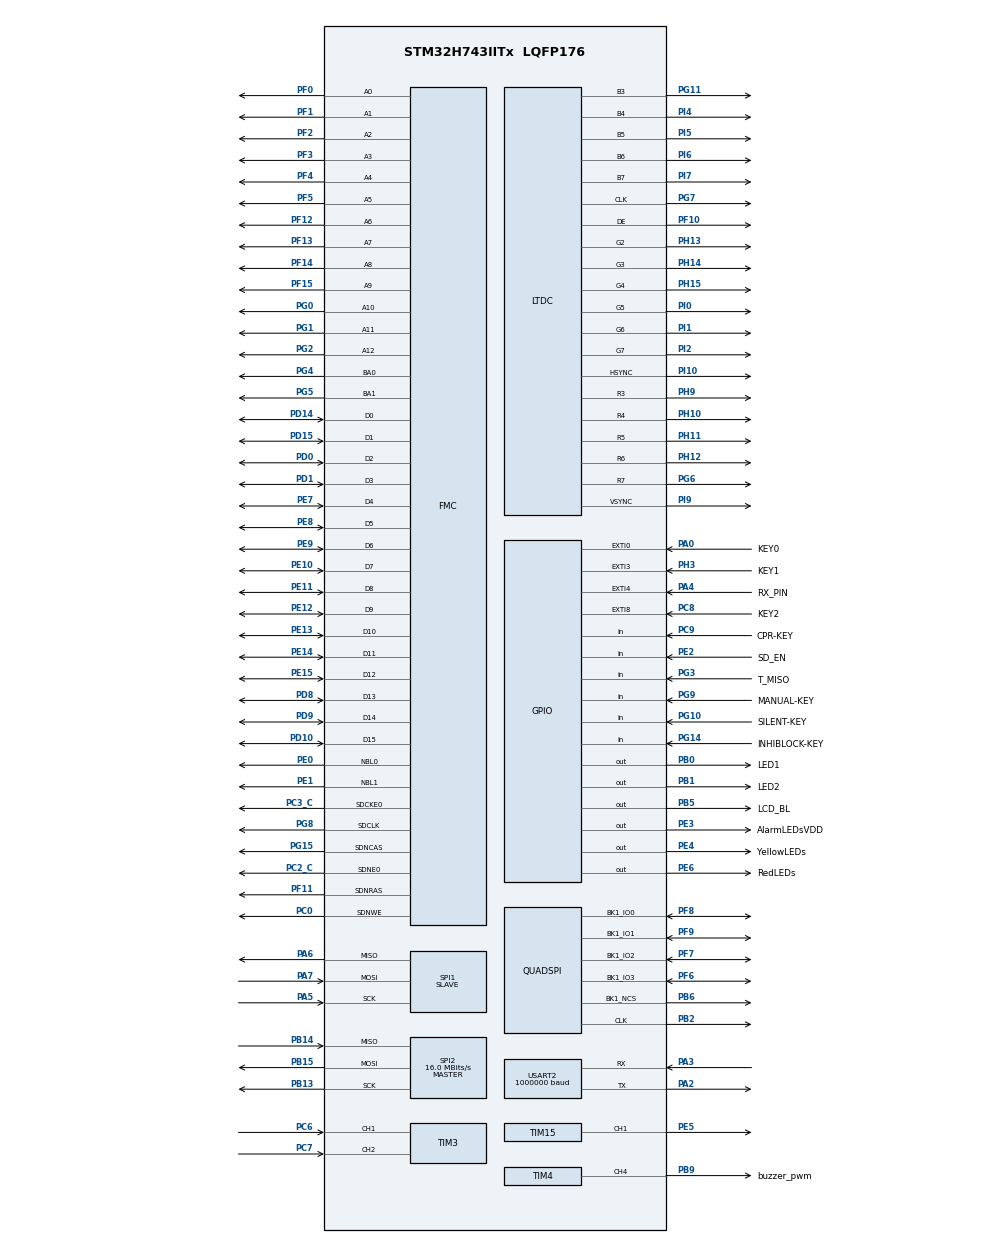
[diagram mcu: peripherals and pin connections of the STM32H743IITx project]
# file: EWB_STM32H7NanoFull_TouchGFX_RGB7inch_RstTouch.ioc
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CORTEX_M7.AccessPermission-Cortex_Memory_Protection_Unit_Region1_Settings=MPU_REGION_FULL_ACCESS
CORTEX_M7.AccessPermission-Cortex_Memory_Protection_Unit_Region2_Settings=MPU_REGION_FULL_ACCESS
CORTEX_M7.AccessPermission-Cortex_Memory_Protection_Unit_Region3_Settings=MPU_REGION_FULL_ACCESS
CORTEX_M7.AccessPermission-Cortex_Memory_Protection_Unit_Region4_Settings=MPU_REGION_FULL_ACCESS
CORTEX_M7.AccessPermission-Cortex_Memory_Protection_Unit_Region5_Settings=MPU_REGION_FULL_ACCESS
CORTEX_M7.AccessPermission-Cortex_Memory_Protection_Unit_Region6_Settings=MPU_REGION_FULL_ACCESS
CORTEX_M7.AccessPermission-Cortex_Memory_Protection_Unit_Region7_Settings=MPU_REGION_FULL_ACCESS
CORTEX_M7.BaseAddress-Cortex_Memory_Protection_Unit_Region1_Settings=0x90000000
CORTEX_M7.BaseAddress-Cortex_Memory_Protection_Unit_Region2_Settings=0xC0000000
CORTEX_M7.BaseAddress-Cortex_Memory_Protection_Unit_Region3_Settings=0x20000000
CORTEX_M7.BaseAddress-Cortex_Memory_Protection_Unit_Region4_Settings=0x24000000
CORTEX_M7.BaseAddress-Cortex_Memory_Protection_Unit_Region5_Settings=0x30000000
CORTEX_M7.BaseAddress-Cortex_Memory_Protection_Unit_Region6_Settings=0x38000000
CORTEX_M7.BaseAddress-Cortex_Memory_Protection_Unit_Region7_Settings=0x60000000
CORTEX_M7.CPU_DCache=Enabled
CORTEX_M7.CPU_ICache=Enabled
CORTEX_M7.DisableExec-Cortex_Memory_Protection_Unit_Region0_Settings=MPU_INSTRUCTION_ACCESS_DISABLE
CORTEX_M7.DisableExec-Cortex_Memory_Protection_Unit_Region2_Settings=MPU_INSTRUCTION_ACCESS_ENABLE
CORTEX_M7.Enable-Cortex_Memory_Protection_Unit_Region0_Settings=MPU_REGION_ENABLE
CORTEX_M7.Enable-Cortex_Memory_Protection_Unit_Region1_Settings=MPU_REGION_ENABLE
CORTEX_M7.Enable-Cortex_Memory_Protection_Unit_Region2_Settings=MPU_REGION_ENABLE
CORTEX_M7.Enable-Cortex_Memory_Protection_Unit_Region3_Settings=MPU_REGION_ENABLE
CORTEX_M7.Enable-Cortex_Memory_Protection_Unit_Region4_Settings=MPU_REGION_ENABLE
CORTEX_M7.Enable-Cortex_Memory_Protection_Unit_Region5_Settings=MPU_REGION_ENABLE
CORTEX_M7.Enable-Cortex_Memory_Protection_Unit_Region6_Settings=MPU_REGION_ENABLE
CORTEX_M7.Enable-Cortex_Memory_Protection_Unit_Region7_Settings=MPU_REGION_ENABLE
CORTEX_M7.Enable-Cortex_Memory_Protection_Unit_Region8_Settings=__NULL
CORTEX_M7.IsBufferable-Cortex_Memory_Protection_Unit_Region2_Settings=MPU_ACCESS_BUFFERABLE
CORTEX_M7.IsBufferable-Cortex_Memory_Protection_Unit_Region3_Settings=MPU_ACCESS_BUFFERABLE
CORTEX_M7.IsBufferable-Cortex_Memory_Protection_Unit_Region4_Settings=MPU_ACCESS_BUFFERABLE
CORTEX_M7.IsBufferable-Cortex_Memory_Protection_Unit_Region5_Settings=MPU_ACCESS_BUFFERABLE
CORTEX_M7.IsBufferable-Cortex_Memory_Protection_Unit_Region6_Settings=MPU_ACCESS_BUFFERABLE
CORTEX_M7.IsCacheable-Cortex_Memory_Protection_Unit_Region1_Settings=MPU_ACCESS_CACHEABLE
CORTEX_M7.IsCacheable-Cortex_Memory_Protection_Unit_Region2_Settings=MPU_ACCESS_CACHEABLE
CORTEX_M7.IsCacheable-Cortex_Memory_Protection_Unit_Region3_Settings=MPU_ACCESS_CACHEABLE
CORTEX_M7.IsCacheable-Cortex_Memory_Protection_Unit_Region4_Settings=MPU_ACCESS_CACHEABLE
CORTEX_M7.IsCacheable-Cortex_Memory_Protection_Unit_Region5_Settings=MPU_ACCESS_CACHEABLE
CORTEX_M7.IsCacheable-Cortex_Memory_Protection_Unit_Region6_Settings=MPU_ACCESS_CACHEABLE
CORTEX_M7.IsShareable-Cortex_Memory_Protection_Unit_Region0_Settings=MPU_ACCESS_SHAREABLE
CORTEX_M7.MPU_Control=__NULL
CORTEX_M7.Size-Cortex_Memory_Protection_Unit_Region0_Settings=MPU_REGION_SIZE_4GB
CORTEX_M7.Size-Cortex_Memory_Protection_Unit_Region1_Settings=MPU_REGION_SIZE_32MB
CORTEX_M7.Size-Cortex_Memory_Protection_Unit_Region2_Settings=MPU_REGION_SIZE_32MB
CORTEX_M7.Size-Cortex_Memory_Protection_Unit_Region3_Settings=MPU_REGION_SIZE_128KB
CORTEX_M7.Size-Cortex_Memory_Protection_Unit_Region4_Settings=MPU_REGION_SIZE_512KB
CORTEX_M7.Size-Cortex_Memory_Protection_Unit_Region5_Settings=MPU_REGION_SIZE_512KB
CORTEX_M7.Size-Cortex_Memory_Protection_Unit_Region6_Settings=MPU_REGION_SIZE_64KB
CORTEX_M7.Size-Cortex_Memory_Protection_Unit_Region7_Settings=MPU_REGION_SIZE_64KB
CORTEX_M7.SubRegionDisable-Cortex_Memory_Protection_Unit_Region0_Settings=0x87
DMA2D.ColorMode=DMA2D_OUTPUT_RGB565
FMC.CASLatency1=FMC_SDRAM_CAS_LATENCY_3
FMC.ColumnBitsNumber1=FMC_SDRAM_COLUMN_BITS_NUM_9
FMC.ExitSelfRefreshDelay1=8
FMC.LoadToActiveDelay1=2
FMC.RCDDelay1=2
FMC.RPDelay1=2
FMC.RPDelay2=2
FMC.ReadBurst1=FMC_SDRAM_RBURST_ENABLE
FMC.ReadBurst2=FMC_SDRAM_RBURST_ENABLE
FMC.ReadPipeDelay1=FMC_SDRAM_RPIPE_DELAY_0
FMC.RowCycleDelay1=7
FMC.RowCycleDelay2=7
FMC.SDClockPeriod1=FMC_SDRAM_CLOCK_PERIOD_2
FMC.SDClockPeriod2=FMC_SDRAM_CLOCK_PERIOD_2
FMC.SelfRefreshTime1=5
FMC.WriteRecoveryTime1=4
LTDC.ActiveH=600
LTDC.ActiveW=800
LTDC.Alpha_L0=255
LTDC.Alpha_L1=255
LTDC.FBStartAdress_L0=0xC0000000
LTDC.Green_L0=0
LTDC.HBP=46
LTDC.HFP=210
LTDC.HSync=1
LTDC.ImageHeight_L0=600
LTDC.ImageHeight_L1=480
LTDC.ImageWidth_L0=800
LTDC.Layers=0
LTDC.PixelFormat_L0=LTDC_PIXEL_FORMAT_RGB565
LTDC.Red_L0=0
LTDC.VBP=23
LTDC.VFP=12
LTDC.VSync=13
LTDC.WindowX0_L0=0
LTDC.WindowX1_L0=800
LTDC.WindowX1_L1=800
LTDC.WindowY0_L0=0
LTDC.WindowY1_L0=600
LTDC.WindowY1_L1=480
Mcu.Family=STM32H7
Mcu.Name=STM32H743IITx
Mcu.Package=LQFP176
NVIC.DMA2D_IRQn=true\:0\:0\:false\:false\:true\:true\:true\:true
NVIC.EXTI0_IRQn=true\:0\:0\:false\:false\:true\:true\:true\:true
NVIC.EXTI3_IRQn=true\:0\:0\:false\:false\:true\:true\:true\:true
NVIC.EXTI4_IRQn=true\:0\:0\:false\:false\:true\:true\:true\:true
NVIC.EXTI9_5_IRQn=true\:0\:0\:false\:false\:true\:true\:true\:true
NVIC.LTDC_ER_IRQn=true\:0\:0\:false\:false\:true\:true\:true\:true
NVIC.LTDC_IRQn=true\:0\:0\:false\:false\:true\:true\:true\:true
NVIC.PriorityGroup=NVIC_PRIORITYGROUP_4
NVIC.SPI1_IRQn=true\:0\:0\:false\:false\:true\:true\:true\:true
NVIC.TIM2_IRQn=true\:0\:0\:false\:false\:true\:true\:true\:true
NVIC.TIM3_IRQn=true\:0\:0\:false\:false\:true\:true\:true\:true
NVIC.TIM6_DAC_IRQn=true\:15\:0\:false\:false\:true\:false\:true\:true
NVIC.TimeBase=TIM6_DAC_IRQn
NVIC.TimeBaseIP=TIM6
PA0.GPIO_Label=KEY0
PA0.GPIO_ModeDefaultEXTI=GPIO_MODE_IT_RISING
PA0.GPIO_PuPd=GPIO_NOPULL
PA0.Signal=GPXTI0
PA13\ (JTMS/SWDIO).Mode=Serial_Wire
PA13\ (JTMS/SWDIO).Signal=DEBUG_JTMS-SWDIO
PA14\ (JTCK/SWCLK).Mode=Serial_Wire
PA14\ (JTCK/SWCLK).Signal=DEBUG_JTCK-SWCLK
PA2.Mode=Asynchronous
PA2.Signal=USART2_TX
PA3.Mode=Asynchronous
PA3.Signal=USART2_RX
PA4.GPIO_Label=RX_PIN
PA4.Signal=GPXTI4
PA5.Mode=Full_Duplex_Slave
PA5.Signal=SPI1_SCK
PA6.Mode=Full_Duplex_Slave
PA6.Signal=SPI1_MISO
PA7.Mode=Full_Duplex_Slave
PA7.Signal=SPI1_MOSI
PB0.GPIO_Label=LED1
PB0.GPIO_Speed=GPIO_SPEED_FREQ_VERY_HIGH
PB0.PinState=GPIO_PIN_RESET
PB0.Signal=GPIO_Output
PB1.GPIO_Label=LED2
PB1.GPIO_Speed=GPIO_SPEED_FREQ_VERY_HIGH
PB1.Signal=GPIO_Output
PB13.Mode=Full_Duplex_Master
PB13.Signal=SPI2_SCK
PB14.Mode=Full_Duplex_Master
PB14.Signal=SPI2_MISO
PB15.Mode=Full_Duplex_Master
PB15.Signal=SPI2_MOSI
PB2.GPIO_Speed=GPIO_SPEED_FREQ_VERY_HIGH
PB2.Mode=Single Bank 1
PB2.Signal=QUADSPI_CLK
PB5.GPIO_Label=LCD_BL
PB5.GPIO_Speed=GPIO_SPEED_FREQ_VERY_HIGH
PB5.PinState=GPIO_PIN_RESET
PB5.Signal=GPIO_Output
PB6.GPIO_FM6=SYSCFG_PMCR_I2C_PB6_FMP
PB6.GPIO_Speed=GPIO_SPEED_FREQ_VERY_HIGH
PB6.Mode=Single Bank 1
PB6.Signal=QUADSPI_BK1_NCS
PB9.GPIO_Label=buzzer_pwm
PB9.Signal=S_TIM4_CH4
PC0.Signal=FMC_SDNWE
PC14-OSC32_IN\ (OSC32_IN).Mode=LSE-External-Oscillator
PC14-OSC32_IN\ (OSC32_IN).Signal=RCC_OSC32_IN
PC15-OSC32_OUT\ (OSC32_OUT).Mode=LSE-External-Oscillator
PC15-OSC32_OUT\ (OSC32_OUT).Signal=RCC_OSC32_OUT
PC2_C.Mode=SdramChipSelect1_1
PC2_C.Signal=FMC_SDNE0
PC3_C.Mode=SdramChipSelect1_1
PC3_C.Signal=FMC_SDCKE0
PC6.GPIO_PuPd=GPIO_PULLUP
PC6.GPIO_Speed=GPIO_SPEED_FREQ_LOW
PC6.Signal=S_TIM3_CH1
PC7.GPIO_PuPd=GPIO_PULLUP
PC7.GPIO_Speed=GPIO_SPEED_FREQ_LOW
PC7.Signal=S_TIM3_CH2
PC8.GPIO_Label=KEY2
PC8.Signal=GPXTI8
PC9.GPIO_Label=CPR-KEY
PC9.GPIO_PuPd=GPIO_PULLUP
PC9.Signal=GPIO_Input
PD0.Signal=FMC_D2_DA2
PD1.Signal=FMC_D3_DA3
PD10.Signal=FMC_D15_DA15
PD14.Signal=FMC_D0_DA0
PD15.Signal=FMC_D1_DA1
PD8.Signal=FMC_D13_DA13
PD9.Signal=FMC_D14_DA14
PE0.Signal=FMC_NBL0
PE1.Signal=FMC_NBL1
PE10.Signal=FMC_D7_DA7
PE11.Signal=FMC_D8_DA8
PE12.Signal=FMC_D9_DA9
PE13.Signal=FMC_D10_DA10
PE14.Signal=FMC_D11_DA11
PE15.Signal=FMC_D12_DA12
PE2.GPIO_Label=SD_EN
PE2.GPIO_PuPd=GPIO_PULLDOWN
PE2.Signal=GPIO_Input
PE3.GPIO_Label=AlarmLEDsVDD
PE3.Signal=GPIO_Output
PE4.GPIO_Label=YellowLEDs
PE4.GPIO_PuPd=GPIO_PULLDOWN
PE4.Signal=GPIO_Output
PE5.Signal=S_TIM15_CH1
PE6.GPIO_Label=RedLEDs
PE6.GPIO_PuPd=GPIO_PULLDOWN
PE6.Signal=GPIO_Output
PE7.Signal=FMC_D4_DA4
PE8.Signal=FMC_D5_DA5
PE9.Signal=FMC_D6_DA6
PF0.Signal=FMC_A0
PF1.Signal=FMC_A1
PF10.GPIO_Speed=GPIO_SPEED_FREQ_VERY_HIGH
PF10.Mode=RGB565
PF10.Signal=LTDC_DE
PF11.Signal=FMC_SDNRAS
PF12.Signal=FMC_A6
PF13.Signal=FMC_A7
PF14.Signal=FMC_A8
PF15.Signal=FMC_A9
PF2.Signal=FMC_A2
PF3.Signal=FMC_A3
PF4.Signal=FMC_A4
PF5.Signal=FMC_A5
PF6.GPIO_Speed=GPIO_SPEED_FREQ_VERY_HIGH
PF6.Mode=Single Bank 1
PF6.Signal=QUADSPI_BK1_IO3
PF7.GPIO_Speed=GPIO_SPEED_FREQ_VERY_HIGH
PF7.Mode=Single Bank 1
PF7.Signal=QUADSPI_BK1_IO2
PF8.GPIO_Speed=GPIO_SPEED_FREQ_VERY_HIGH
PF8.Mode=Single Bank 1
PF8.Signal=QUADSPI_BK1_IO0
PF9.GPIO_Speed=GPIO_SPEED_FREQ_VERY_HIGH
PF9.Mode=Single Bank 1
PF9.Signal=QUADSPI_BK1_IO1
PG0.Signal=FMC_A10
PG1.Signal=FMC_A11
PG10.GPIO_Label=SILENT-KEY
PG10.GPIO_PuPd=GPIO_PULLUP
PG10.Signal=GPIO_Input
PG11.GPIO_Speed=GPIO_SPEED_FREQ_VERY_HIGH
PG11.Mode=RGB565
PG11.Signal=LTDC_B3
PG14.GPIO_Label=INHIBLOCK-KEY
PG14.GPIO_PuPd=GPIO_PULLUP
PG14.Signal=GPIO_Input
PG15.Signal=FMC_SDNCAS
PG2.Signal=FMC_A12
PG3.GPIO_Label=T_MISO
PG3.Signal=GPIO_Input
PG4.Signal=FMC_A14_BA0
PG5.Signal=FMC_A15_BA1
PG6.GPIO_Speed=GPIO_SPEED_FREQ_VERY_HIGH
PG6.Mode=RGB565
PG6.Signal=LTDC_R7
PG7.GPIO_Speed=GPIO_SPEED_FREQ_VERY_HIGH
PG7.Mode=RGB565
PG7.Signal=LTDC_CLK
PG8.Signal=FMC_SDCLK
PG9.GPIO_Label=MANUAL-KEY
PG9.GPIO_PuPd=GPIO_PULLUP
PG9.Signal=GPIO_Input
PH0-OSC_IN\ (PH0).Mode=HSE-External-Oscillator
PH0-OSC_IN\ (PH0).Signal=RCC_OSC_IN
PH1-OSC_OUT\ (PH1).Mode=HSE-External-Oscillator
PH1-OSC_OUT\ (PH1).Signal=RCC_OSC_OUT
PH10.GPIO_Speed=GPIO_SPEED_FREQ_VERY_HIGH
PH10.Mode=RGB565
PH10.Signal=LTDC_R4
PH11.GPIO_Speed=GPIO_SPEED_FREQ_VERY_HIGH
PH11.Mode=RGB565
PH11.Signal=LTDC_R5
PH12.GPIO_Speed=GPIO_SPEED_FREQ_VERY_HIGH
PH12.Mode=RGB565
PH12.Signal=LTDC_R6
PH13.GPIO_Speed=GPIO_SPEED_FREQ_VERY_HIGH
PH13.Mode=RGB565
PH13.Signal=LTDC_G2
PH14.GPIO_Speed=GPIO_SPEED_FREQ_VERY_HIGH
PH14.Mode=RGB565
PH14.Signal=LTDC_G3
PH15.GPIO_Speed=GPIO_SPEED_FREQ_VERY_HIGH
PH15.Mode=RGB565
PH15.Signal=LTDC_G4
PH3.GPIO_Label=KEY1
PH3.Signal=GPXTI3
PH4.GPIO_Pu=GPIO_PULLUP
PH4.GPIO_Speed=GPIO_SPEED_FREQ_VERY_HIGH
PH4.Signal=I2C2_SCL
PH5.GPIO_Pu=GPIO_PULLUP
PH5.GPIO_Speed=GPIO_SPEED_FREQ_VERY_HIGH
PH5.Signal=I2C2_SDA
PH9.GPIO_Speed=GPIO_SPEED_FREQ_VERY_HIGH
PH9.Mode=RGB565
PH9.Signal=LTDC_R3
PI0.GPIO_Speed=GPIO_SPEED_FREQ_VERY_HIGH
PI0.Mode=RGB565
PI0.Signal=LTDC_G5
PI1.GPIO_Speed=GPIO_SPEED_FREQ_VERY_HIGH
PI1.Mode=RGB565
PI1.Signal=LTDC_G6
PI10.GPIO_Speed=GPIO_SPEED_FREQ_VERY_HIGH
PI10.Mode=RGB565
PI10.Signal=LTDC_HSYNC
PI2.GPIO_Speed=GPIO_SPEED_FREQ_VERY_HIGH
PI2.Mode=RGB565
PI2.Signal=LTDC_G7
PI4.GPIO_Speed=GPIO_SPEED_FREQ_VERY_HIGH
PI4.Mode=RGB565
PI4.Signal=LTDC_B4
PI5.GPIO_Speed=GPIO_SPEED_FREQ_VERY_HIGH
PI5.Mode=RGB565
PI5.Signal=LTDC_B5
PI6.GPIO_Speed=GPIO_SPEED_FREQ_VERY_HIGH
PI6.Mode=RGB565
PI6.Signal=LTDC_B6
PI7.GPIO_Speed=GPIO_SPEED_FREQ_VERY_HIGH
PI7.Mode=RGB565
PI7.Signal=LTDC_B7
PI9.GPIO_Speed=GPIO_SPEED_FREQ_VERY_HIGH
PI9.Mode=RGB565
PI9.Signal=LTDC_VSYNC
ProjectManager.HeapSize=0x2000
ProjectManager.StackSize=0x2000
ProjectManager.TargetToolchain=MDK-ARM V5.32
QUADSPI.ChipSelectHighTime=QSPI_CS_HIGH_TIME_1_CYCLE
QUADSPI.ClockMode=QSPI_CLOCK_MODE_3
QUADSPI.ClockPrescaler=4
QUADSPI.FifoThreshold=4
QUADSPI.FlashSize=24
QUADSPI.SampleShifting=QSPI_SAMPLE_SHIFTING_HALFCYCLE
RCC.ADCFreq_Value=133000000
RCC.APB1Freq_Value=100000000
RCC.APB2Freq_Value=100000000
RCC.APB3Freq_Value=100000000
RCC.APB4Freq_Value=100000000
RCC.CortexFreq_Value=400000000
RCC.D1PPRE=RCC_APB3_DIV2
RCC.D2PPRE1=RCC_APB1_DIV2
RCC.D2PPRE2=RCC_APB2_DIV2
RCC.D3PPRE=RCC_APB4_DIV2
RCC.DIVM1=5
RCC.DIVM2=25
RCC.DIVM3=25
RCC.DIVN1=160
RCC.DIVN2=266
RCC.DIVN3=330
RCC.DIVQ1=8
RCC.DIVR1=4
RCC.DIVR3=10
RCC.FMCCLockSelection=RCC_FMCCLKSOURCE_PLL2
RCC.HCLKFreq_Value=200000000
RCC.HPRE=RCC_HCLK_DIV2
RCC.LSE_Drive_Capability=RCC_LSEDRIVE_MEDIUMHIGH
RCC.PLL2FRACN=0
RCC.PLL3FRACN=0
RCC.PLLFRACN=0
RCC.PLLSourceVirtual=RCC_PLLSOURCE_HSE
RCC.QSPICLockSelection=RCC_QSPICLKSOURCE_PLL
RCC.RTCClockSelection=RCC_RTCCLKSOURCE_LSE
RCC.SPI123CLockSelection=RCC_SPI123CLKSOURCE_CLKP
RCC.SYSCLKFreq_VALUE=400000000
RCC.SYSCLKSource=RCC_SYSCLKSOURCE_PLLCLK
RCC.USBFreq_Value=100000000
RTC.Date=7
RTC.Format=RTC_FORMAT_BIN
RTC.Hours=18
RTC.Minutes=20
RTC.Month=RTC_MONTH_NOVEMBER
RTC.Seconds=30
RTC.WeekDay=RTC_WEEKDAY_TUESDAY
RTC.Year=23
SH.FMC_A0.0=FMC_A0,13b-sda1
SH.FMC_A1.0=FMC_A1,13b-sda1
SH.FMC_A10.0=FMC_A10,13b-sda1
SH.FMC_A11.0=FMC_A11,13b-sda1
SH.FMC_A12.0=FMC_A12,13b-sda1
SH.FMC_A14_BA0.0=FMC_BA0,FourSdramBanks1
SH.FMC_A15_BA1.0=FMC_BA1,FourSdramBanks1
SH.FMC_A2.0=FMC_A2,13b-sda1
SH.FMC_A3.0=FMC_A3,13b-sda1
SH.FMC_A4.0=FMC_A4,13b-sda1
SH.FMC_A5.0=FMC_A5,13b-sda1
SH.FMC_A6.0=FMC_A6,13b-sda1
SH.FMC_A7.0=FMC_A7,13b-sda1
SH.FMC_A8.0=FMC_A8,13b-sda1
SH.FMC_A9.0=FMC_A9,13b-sda1
SH.FMC_D0_DA0.0=FMC_D0,sd-16b-d1
SH.FMC_D10_DA10.0=FMC_D10,sd-16b-d1
SH.FMC_D11_DA11.0=FMC_D11,sd-16b-d1
SH.FMC_D12_DA12.0=FMC_D12,sd-16b-d1
SH.FMC_D13_DA13.0=FMC_D13,sd-16b-d1
SH.FMC_D14_DA14.0=FMC_D14,sd-16b-d1
SH.FMC_D15_DA15.0=FMC_D15,sd-16b-d1
SH.FMC_D1_DA1.0=FMC_D1,sd-16b-d1
SH.FMC_D2_DA2.0=FMC_D2,sd-16b-d1
SH.FMC_D3_DA3.0=FMC_D3,sd-16b-d1
SH.FMC_D4_DA4.0=FMC_D4,sd-16b-d1
SH.FMC_D5_DA5.0=FMC_D5,sd-16b-d1
SH.FMC_D6_DA6.0=FMC_D6,sd-16b-d1
SH.FMC_D7_DA7.0=FMC_D7,sd-16b-d1
SH.FMC_D8_DA8.0=FMC_D8,sd-16b-d1
SH.FMC_D9_DA9.0=FMC_D9,sd-16b-d1
SH.FMC_NBL0.0=FMC_NBL0,Sd2ByteEnable1
SH.FMC_NBL1.0=FMC_NBL1,Sd2ByteEnable1
SH.FMC_SDCLK.0=FMC_SDCLK,13b-sda1
SH.FMC_SDNCAS.0=FMC_SDNCAS,13b-sda1
SH.FMC_SDNRAS.0=FMC_SDNRAS,13b-sda1
SH.FMC_SDNWE.0=FMC_SDNWE,13b-sda1
SH.S_TIM15_CH1.0=TIM15_CH1,PWM Generation1 CH1
SH.S_TIM3_CH1.0=TIM3_CH1,Encoder_Interface
SH.S_TIM3_CH2.0=TIM3_CH2,Encoder_Interface
SH.S_TIM4_CH4.0=TIM4_CH4,PWM Generation4 CH4
SPI1.DataSize=SPI_DATASIZE_8BIT
SPI1.Direction=SPI_DIRECTION_2LINES
SPI1.Mode=SPI_MODE_SLAVE
SPI1.VirtualType=VM_SLAVE
SPI2.BaudRatePrescaler=SPI_BAUDRATEPRESCALER_4
SPI2.CalculateBaudRate=16.0 MBits/s
SPI2.DataSize=SPI_DATASIZE_8BIT
SPI2.Direction=SPI_DIRECTION_2LINES
SPI2.Mode=SPI_MODE_MASTER
SPI2.VirtualType=VM_MASTER
STMicroelectronics.X-CUBE-TOUCHGFX.4.20.0.ApplicationCcGraphicsJjApplication=TouchGFXOoGenerator
STMicroelectronics.X-CUBE-TOUCHGFX.4.20.0.tgfx_address1=0xC0000000
STMicroelectronics.X-CUBE-TOUCHGFX.4.20.0.tgfx_address2=0xC00EA600
STMicroelectronics.X-CUBE-TOUCHGFX.4.20.0.tgfx_buffering_strategy=Double
STMicroelectronics.X-CUBE-TOUCHGFX.4.20.0.tgfx_display_interface=disp_ltdc
STMicroelectronics.X-CUBE-TOUCHGFX.4.20.0.tgfx_hardware_accelerator=dma_2d
STMicroelectronics.X-CUBE-TOUCHGFX.4.20.0.tgfx_location=By Address
STMicroelectronics.X-CUBE-TOUCHGFX.4.20.0.tgfx_video=Disabled
STMicroelectronics.X-CUBE-TOUCHGFX.4.20.0.tgfx_video_buffer_format=RGB565\:2
STMicroelectronics.X-CUBE-TOUCHGFX.4.20.0.tgfx_video_height=272
STMicroelectronics.X-CUBE-TOUCHGFX.4.20.0.tgfx_video_strategy=2
STMicroelectronics.X-CUBE-TOUCHGFX.4.20.0.tgfx_video_streams=1
STMicroelectronics.X-CUBE-TOUCHGFX.4.20.0.tgfx_video_width=480
STMicroelectronics.X-CUBE-TOUCHGFX.4.20.0.tgfx_vsync=vsync_ltdc
STMicroelectronics.X-CUBE-TOUCHGFX.4.20.0_IsPackSelfContextualization=true
TIM15.Channel-PWM\ Generation1\ CH1=TIM_CHANNEL_1
TIM15.Period=99
TIM15.Prescaler=1999
TIM2.Period=9999
TIM2.Prescaler=999
TIM3.EncoderMode=TIM_ENCODERMODE_TI12
TIM3.IC1Filter=10
TIM3.IC1Polarity=TIM_ICPOLARITY_FALLING
TIM3.IC2Filter=10
TIM3.IC2Polarity=TIM_ICPOLARITY_FALLING
TIM4.Channel-PWM\ Generation4\ CH4=TIM_CHANNEL_4
TIM4.Period=99
TIM4.Prescaler=2500
USART2.BaudRate=1000000
USART2.VirtualMode-Asynchronous=VM_ASYNC
VP_CRC_VS_CRC.Mode=CRC_Activate
VP_DMA2D_VS_DMA2D.Mode=DMA2D_Activate
VP_RTC_VS_RTC_Activate.Mode=RTC_Enabled
VP_RTC_VS_RTC_Calendar.Mode=RTC_Calendar
VP_STMicroelectronics.X-CUBE-TOUCHGFX_VS_GraphicsJjApplication_4.20.0.Mode=GraphicsJjApplication
VP_SYS_VS_tim6.Mode=TIM6
VP_TIM15_VS_ClockSourceINT.Mode=Internal
VP_TIM2_VS_ClockSourceINT.Mode=Internal
VP_TIM4_VS_ClockSourceINT.Mode=Internal
board=custom

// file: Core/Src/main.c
/* USER CODE BEGIN Header */
/**
  ******************************************************************************
  * @file           : main.c
  * @brief          : Main program body
  ******************************************************************************
  * @attention
  *
  * <h2><center>&copy; Copyright (c) 2022 STMicroelectronics.
  * All rights reserved.</center></h2>
  *
  * This software component is licensed by ST under Ultimate Liberty license
  * SLA0044, the "License"; You may not use this file except in compliance with
  * the License. You may obtain a copy of the License at:
  *                             www.st.com/SLA0044
  *
  ******************************************************************************
  */
/* USER CODE END Header */
#include "main.h"
#include "crc.h"
#include "dma2d.h"
#include "ltdc.h"
#include "quadspi.h"
#include "rtc.h"
#include "spi.h"
#include "tim.h"
#include "usart.h"
#include "gpio.h"
#include "fmc.h"
#include "app_touchgfx.h"

/* USER CODE BEGIN Includes */
#include <string.h>
#include "dwt_stm32_delay.h"
#include "touch_800x480.h"
#include "stdlib.h"
#include "stdio.h"
#include "Buzzer.h"
/* USER CODE END Includes */

/* USER CODE BEGIN PD */
#define BUFFER_SIZE 700

/* USER CODE END PD */

/* USER CODE BEGIN PV */
int vdd = 0;
int yel = 0;
int red = 0;

uint8_t tx_data[700] = "data";
int config_ok = 1; //yes = 1 / no = 0
int state_IE = 0;  //I = 0 / E = 1
int state_I_begin = 0; //begin I = 0
int state_E_begin = 0; //begin E = 0
int counter_timer_I = 0; //time inspritory
int counter_timer_E = 0; //time expirtory
int Counter_timer_T = 0;
int my_t = 0; //for recording
int my_value = 0;
int taghsim = 0;

uint8_t isAlerting = 0; // 0:false, 1:true
float flag_startVent = 0;
float lockScreen_intval = 0; // 0:off, 1:on
float CPR_intval = 0; // 0:off, 1:on
int isLockChanged = 0;
int isCPRChanged = 0;
float manualBreath_intval = 0;
float silent_intval = 0;

float Voltage = 0;
uint16_t VoltageByte;

float RR_real;
float Ti_real;
float TiInspPause_real;
float Te_real;
float VT_real;
float VTi_real;
float VTe_real;
float flow_real;
float FiO2_real=21;
float SPO2_real;
float LeakExp_real;
float pressure_real;
float pip_real;
float peep_real;
float PIF_real;
float IPP_real;
float CMPL_real;
float AVP_real;
float Patm_real;
float leak_real;
float MVe_real;
float MVi_real;
float Res_real;
float alarm_real[6];
float bat_real;
float PEF_real;
float RSBI_real;
float SpontTrig_real;
float SpontCycle_real;
float circuitDis_real;
float pulseRate_real;
float obstruction_real;
float check_data;
float measureBattTime_real;
float externalDC_real;
float tightness_result;
float flowSensor_forward_result;
float flowSensor_backward_result;
float calib_process;

float old_check_data = 0;
float fault_recieve = 0; // 0 no fault // 1 fault in recieve

RTC_TimeTypeDef RTC_Time;
RTC_DateTypeDef RTC_Date;

uint32_t flag = 0;
uint32_t record=0;

uint16_t x,y;
int resetIT=0;

uint8_t data[4]="data";

uint8_t rx_buffer[BUFFER_SIZE] = {0};
//uint8_t tx_buffer[BUFFER_SIZE] = {0};
int counter=0;
/* USER CODE END PV */

void SystemClock_Config(void);
void PeriphCommonClock_Config(void);

/* USER CODE BEGIN 0 */
void HAL_SPI_RxCpltCallback(SPI_HandleTypeDef *hspi)
{
	counter++;
	HAL_SPI_Receive_IT(&hspi1,rx_buffer,BUFFER_SIZE);

	if(rx_buffer[0]=='d' && rx_buffer[1]=='t')
	{
		//assign variables
		memcpy(&RR_real, rx_buffer + 6, sizeof(float));
		memcpy(&peep_real, rx_buffer + 13, sizeof(float));
		memcpy(&pip_real, rx_buffer + 20, sizeof(float));
		memcpy(&VT_real, rx_buffer + 27, sizeof(float));
		memcpy(&VTe_real, rx_buffer + 34, sizeof(float));
		memcpy(&Ti_real, rx_buffer + 41, sizeof(float));
		memcpy(&Te_real, rx_buffer + 48, sizeof(float));
		memcpy(&PIF_real, rx_buffer + 55, sizeof(float));
		memcpy(&MVi_real, rx_buffer + 62, sizeof(float));
		memcpy(&MVe_real, rx_buffer + 69, sizeof(float));
		memcpy(&AVP_real, rx_buffer + 76, sizeof(float));
		memcpy(&leak_real, rx_buffer + 83, sizeof(float));
		memcpy(&pressure_real, rx_buffer + 90, sizeof(float));
		memcpy(&CMPL_real, rx_buffer + 97, sizeof(float));
		//memcpy(&FiO2_real, rx_buffer + 104, sizeof(float));
		memcpy(&IPP_real, rx_buffer + 111, sizeof(float));
		memcpy(&Res_real, rx_buffer + 118, sizeof(float));
		memcpy(&SpontTrig_real, rx_buffer + 125, sizeof(float));
		memcpy(&flow_real, rx_buffer + 132, sizeof(float));
		memcpy(&Patm_real, rx_buffer + 139, sizeof(float));
		memcpy(&bat_real, rx_buffer + 146, sizeof(float));
		memcpy(&PEF_real, rx_buffer + 153, sizeof(float));
		memcpy(&VTi_real, rx_buffer + 160, sizeof(float));
	  memcpy(&check_data, rx_buffer + 167, sizeof(float));
		memcpy(&LeakExp_real, rx_buffer + 174, sizeof(float));
		memcpy(&RSBI_real, rx_buffer + 181, sizeof(float));
		//memcpy(&SpontTrig_real, rx_buffer + 188, sizeof(float));
		memcpy(&SpontCycle_real, rx_buffer + 195, sizeof(float));
		memcpy(&measureBattTime_real, rx_buffer + 202, sizeof(float));
		memcpy(&alarm_real[0], rx_buffer + 209, sizeof(float));
		memcpy(&alarm_real[1], rx_buffer + 216, sizeof(float));
		memcpy(&alarm_real[2], rx_buffer + 223, sizeof(float));
		memcpy(&alarm_real[3], rx_buffer + 230, sizeof(float));
		memcpy(&alarm_real[4], rx_buffer + 237, sizeof(float));
		memcpy(&alarm_real[5], rx_buffer + 244, sizeof(float));
		memcpy(&externalDC_real, rx_buffer + 251, sizeof(float));
		memcpy(&SPO2_real, rx_buffer + 258, sizeof(float));
		memcpy(&pulseRate_real, rx_buffer + 265, sizeof(float));
		memcpy(&calib_process, rx_buffer + 272, sizeof(float));
		memcpy(&tightness_result, rx_buffer + 279, sizeof(float));
		memcpy(&flowSensor_forward_result, rx_buffer + 286, sizeof(float));
		memcpy(&flowSensor_backward_result, rx_buffer + 293, sizeof(float));

	}
	else // data is wrong
	{
		//resetIT++;
		__HAL_SPI_DISABLE_IT(&hspi1, SPI_IT_RXNE);
		HAL_SPI_DeInit(&hspi1);
		__HAL_SPI_CLEAR_OVRFLAG(&hspi1);
		MX_SPI1_Init();
		HAL_SPI_Receive_IT(&hspi1,rx_buffer,BUFFER_SIZE);
	}

}
//void HAL_GPIO_EXTI_Callback(uint16_t GPIO_Pin)
//{
//	if(GPIO_Pin == Receive_pin_Pin)
//	{
//		counter++;
//		HAL_UART_Receive(&huart2, rx_data, 50, 10);
//	}
//}

uint8_t TouchIsCalibrated = 0;

uint16_t x,y;
int16_t encoderCounter = 0;
int16_t key1 = 0;
void HAL_TIM_IC_CaptureCallback(TIM_HandleTypeDef *htim)
{
	encoderCounter=(int16_t)__HAL_TIM_GET_COUNTER(htim);
	key1 = encoderCounter/4;
}

//------------ --------------- ----------------

//------------ ---------------- ---------------

//void HAL_UART_RxCpltCallback(UART_HandleTypeDef *huart)
//{
//	counter++;
//	//HAL_UART_Receive_IT(&huart2, rx_data, 8);
//	HAL_UART_Receive_DMA(&huart2, rx_data, 100);
//}

//------------ --------------- ----------------
//------------ ---------------- ---------------

/* USER CODE END 0 */

int main(void)
{

  /* Enable I-Cache---------------------------------------------------------*/
  SCB_EnableICache();

  /* Enable D-Cache---------------------------------------------------------*/
  SCB_EnableDCache();

  /* MCU Configuration--------------------------------------------------------*/

  /* Reset of all peripherals, Initializes the Flash interface and the Systick. */
  HAL_Init();

  /* Configure the system clock */
  SystemClock_Config();

/* Configure the peripherals common clocks */
  PeriphCommonClock_Config();

  /* Initialize all configured peripherals */
  MX_GPIO_Init();
  MX_FMC_Init();
  MX_LTDC_Init();
  MX_QUADSPI_Init();
  MX_CRC_Init();
  MX_RTC_Init();
  MX_USART2_UART_Init();
  MX_DMA2D_Init();
  MX_SPI1_Init();
  MX_TIM3_Init();
  MX_TIM15_Init();
  MX_SPI2_Init();
  MX_TIM4_Init();
  MX_TIM2_Init();
  MX_TouchGFX_Init();
  /* USER CODE BEGIN 2 */

	Touch_Init();
	DWT_Delay_Init();
  //HAL_GPIO_WritePin(LCD_BL_GPIO_Port, LCD_BL_Pin, GPIO_PIN_SET);
	HAL_TIM_Encoder_Start_IT(&htim3, TIM_CHANNEL_ALL);

	HAL_TIM_Base_Start_IT(&htim2);
	//HAL_UAR`T_Receive_IT(&huart2, rx_data, 8);
//	HAL_UART_Receive_DMA(&huart2, rx_data, 8);
	HAL_SPI_Receive_IT(&hspi1,rx_buffer,BUFFER_SIZE);

	TIM15->CCR1 = 75; //initialize the light
	HAL_TIM_PWM_Start(&htim15, TIM_CHANNEL_1);
	HAL_TIM_PWM_Start(&htim4, TIM_CHANNEL_4);

  HAL_GPIO_WritePin(YellowLEDs_GPIO_Port, YellowLEDs_Pin, 0);
  HAL_GPIO_WritePin(RedLEDs_GPIO_Port, RedLEDs_Pin, 0);
	HAL_GPIO_WritePin(AlarmLEDsVDD_GPIO_Port, AlarmLEDsVDD_Pin, 0);

  /* USER CODE END 2 */

  /* Infinite loop */
  /* USER CODE BEGIN WHILE */

  while (1)
  {
//  HAL_GPIO_WritePin(YellowLEDs_GPIO_Port, YellowLEDs_Pin, yel);
//  HAL_GPIO_WritePin(RedLEDs_GPIO_Port, RedLEDs_Pin, red);
//	HAL_GPIO_WritePin(AlarmLEDsVDD_GPIO_Port, AlarmLEDsVDD_Pin, vdd);

		if(fault_recieve == 1)
		{
			resetIT++;
			fault_recieve = 0;
			__HAL_SPI_DISABLE_IT(&hspi1, SPI_IT_RXNE);
			HAL_SPI_DeInit(&hspi1);
			__HAL_SPI_CLEAR_OVRFLAG(&hspi1);
			MX_SPI1_Init();
			HAL_SPI_Receive_IT(&hspi1,rx_buffer,BUFFER_SIZE);
		  HAL_SPI_Transmit(&hspi2,tx_data,700,10);
		}
    /* USER CODE END WHILE */

  MX_TouchGFX_Process();
  }
}

void SystemClock_Config(void)
{
  RCC_OscInitTypeDef RCC_OscInitStruct = {0};
  RCC_ClkInitTypeDef RCC_ClkInitStruct = {0};

  /** Supply configuration update enable
  */
  HAL_PWREx_ConfigSupply(PWR_LDO_SUPPLY);

  /** Configure the main internal regulator output voltage
  */
  __HAL_PWR_VOLTAGESCALING_CONFIG(PWR_REGULATOR_VOLTAGE_SCALE1);

  while(!__HAL_PWR_GET_FLAG(PWR_FLAG_VOSRDY)) {}

  /** Configure LSE Drive Capability
  */
  HAL_PWR_EnableBkUpAccess();
  __HAL_RCC_LSEDRIVE_CONFIG(RCC_LSEDRIVE_MEDIUMHIGH);

  /** Macro to configure the PLL clock source
  */
  __HAL_RCC_PLL_PLLSOURCE_CONFIG(RCC_PLLSOURCE_HSE);

  /** Initializes the RCC Oscillators according to the specified parameters
  * in the RCC_OscInitTypeDef structure.
  */
  RCC_OscInitStruct.OscillatorType = RCC_OSCILLATORTYPE_HSI|RCC_OSCILLATORTYPE_HSE
                              |RCC_OSCILLATORTYPE_LSE;
  RCC_OscInitStruct.HSEState = RCC_HSE_ON;
  RCC_OscInitStruct.LSEState = RCC_LSE_ON;
  RCC_OscInitStruct.HSIState = RCC_HSI_DIV1;
  RCC_OscInitStruct.HSICalibrationValue = RCC_HSICALIBRATION_DEFAULT;
  RCC_OscInitStruct.PLL.PLLState = RCC_PLL_ON;
  RCC_OscInitStruct.PLL.PLLSource = RCC_PLLSOURCE_HSE;
  RCC_OscInitStruct.PLL.PLLM = 5;
  RCC_OscInitStruct.PLL.PLLN = 160;
  RCC_OscInitStruct.PLL.PLLP = 2;
  RCC_OscInitStruct.PLL.PLLQ = 8;
  RCC_OscInitStruct.PLL.PLLR = 4;
  RCC_OscInitStruct.PLL.PLLRGE = RCC_PLL1VCIRANGE_2;
  RCC_OscInitStruct.PLL.PLLVCOSEL = RCC_PLL1VCOWIDE;
  RCC_OscInitStruct.PLL.PLLFRACN = 0;
  if (HAL_RCC_OscConfig(&RCC_OscInitStruct) != HAL_OK)
  {
    Error_Handler();
  }

  /** Initializes the CPU, AHB and APB buses clocks
  */
  RCC_ClkInitStruct.ClockType = RCC_CLOCKTYPE_HCLK|RCC_CLOCKTYPE_SYSCLK
                              |RCC_CLOCKTYPE_PCLK1|RCC_CLOCKTYPE_PCLK2
                              |RCC_CLOCKTYPE_D3PCLK1|RCC_CLOCKTYPE_D1PCLK1;
  RCC_ClkInitStruct.SYSCLKSource = RCC_SYSCLKSOURCE_PLLCLK;
  RCC_ClkInitStruct.SYSCLKDivider = RCC_SYSCLK_DIV1;
  RCC_ClkInitStruct.AHBCLKDivider = RCC_HCLK_DIV2;
  RCC_ClkInitStruct.APB3CLKDivider = RCC_APB3_DIV2;
  RCC_ClkInitStruct.APB1CLKDivider = RCC_APB1_DIV2;
  RCC_ClkInitStruct.APB2CLKDivider = RCC_APB2_DIV2;
  RCC_ClkInitStruct.APB4CLKDivider = RCC_APB4_DIV2;

  if (HAL_RCC_ClockConfig(&RCC_ClkInitStruct, FLASH_LATENCY_2) != HAL_OK)
  {
    Error_Handler();
  }
}

void PeriphCommonClock_Config(void)
{
  RCC_PeriphCLKInitTypeDef PeriphClkInitStruct = {0};

  /** Initializes the peripherals clock
  */
  PeriphClkInitStruct.PeriphClockSelection = RCC_PERIPHCLK_CKPER;
  PeriphClkInitStruct.CkperClockSelection = RCC_CLKPSOURCE_HSI;
  if (HAL_RCCEx_PeriphCLKConfig(&PeriphClkInitStruct) != HAL_OK)
  {
    Error_Handler();
  }
}

void HAL_TIM_PeriodElapsedCallback(TIM_HandleTypeDef *htim)
{
  if (htim->Instance == TIM6) {
    HAL_IncTick();
  }
}

void Error_Handler(void)
{
  __disable_irq();
  while (1)
  {
  }
}
